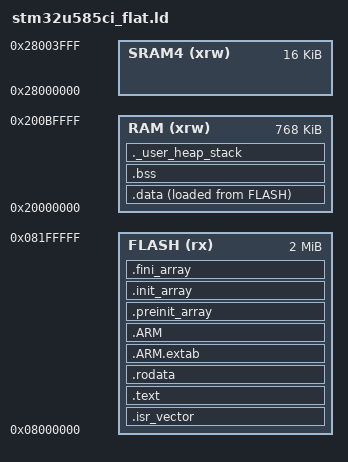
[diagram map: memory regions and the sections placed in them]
/*
 * STM32U585CI linker script - standalone (no bootloader), TrustZone off.
 *
 * Flash: 2048 KB @ 0x08000000
 * SRAM:   768 KB @ 0x20000000 (SRAM1 + SRAM2 + SRAM3)
 * SRAM4:   16 KB @ 0x28000000 (unused)
 *
 * The stack sits at the top of SRAM. The heap runs from the end of .bss up
 * to the bottom of the stack (see _sbrk in src/stubs.c).
 */
ENTRY(Reset_Handler)

_estack = ORIGIN(RAM) + LENGTH(RAM);

_Min_Heap_Size  = 0x10000;  /*  64 KB minimum heap */
_Min_Stack_Size = 0x20000;  /* 128 KB stack */

MEMORY
{
  FLASH (rx)  : ORIGIN = 0x08000000, LENGTH = 2048K
  RAM   (xrw) : ORIGIN = 0x20000000, LENGTH = 768K
  SRAM4 (xrw) : ORIGIN = 0x28000000, LENGTH = 16K
}

SECTIONS
{
  .isr_vector :
  {
    . = ALIGN(8);
    KEEP(*(.isr_vector))
    . = ALIGN(8);
  } >FLASH

  .text :
  {
    . = ALIGN(8);
    *(.text)
    *(.text*)
    *(.glue_7)
    *(.glue_7t)
    *(.eh_frame)
    KEEP(*(.init))
    KEEP(*(.fini))
    . = ALIGN(8);
    _etext = .;
  } >FLASH

  .rodata :
  {
    . = ALIGN(8);
    *(.rodata)
    *(.rodata*)
    . = ALIGN(8);
  } >FLASH

  .ARM.extab (READONLY) :
  {
    . = ALIGN(8);
    *(.ARM.extab* .gnu.linkonce.armextab.*)
    . = ALIGN(8);
  } >FLASH

  .ARM (READONLY) :
  {
    . = ALIGN(8);
    __exidx_start = .;
    *(.ARM.exidx*)
    __exidx_end = .;
    . = ALIGN(8);
  } >FLASH

  .preinit_array (READONLY) :
  {
    . = ALIGN(8);
    PROVIDE_HIDDEN(__preinit_array_start = .);
    KEEP(*(.preinit_array*))
    PROVIDE_HIDDEN(__preinit_array_end = .);
    . = ALIGN(8);
  } >FLASH

  .init_array (READONLY) :
  {
    . = ALIGN(8);
    PROVIDE_HIDDEN(__init_array_start = .);
    KEEP(*(SORT(.init_array.*)))
    KEEP(*(.init_array*))
    PROVIDE_HIDDEN(__init_array_end = .);
    . = ALIGN(8);
  } >FLASH

  .fini_array (READONLY) :
  {
    . = ALIGN(8);
    PROVIDE_HIDDEN(__fini_array_start = .);
    KEEP(*(SORT(.fini_array.*)))
    KEEP(*(.fini_array*))
    PROVIDE_HIDDEN(__fini_array_end = .);
    . = ALIGN(8);
  } >FLASH

  _sidata = LOADADDR(.data);

  .data :
  {
    . = ALIGN(8);
    _sdata = .;
    *(.data)
    *(.data*)
    . = ALIGN(8);
    _edata = .;
  } >RAM AT> FLASH

  . = ALIGN(8);
  .bss :
  {
    _sbss = .;
    __bss_start__ = _sbss;
    *(.bss)
    *(.bss*)
    *(COMMON)
    . = ALIGN(8);
    _ebss = .;
    __bss_end__ = _ebss;
  } >RAM

  /* Check that there is enough RAM left for the minimum heap and the
   * stack */
  ._user_heap_stack :
  {
    . = ALIGN(8);
    PROVIDE(end = .);
    PROVIDE(_end = .);
    . = . + _Min_Heap_Size;
    . = . + _Min_Stack_Size;
    . = ALIGN(8);
  } >RAM

  .ARM.attributes 0 : { *(.ARM.attributes) }
}
